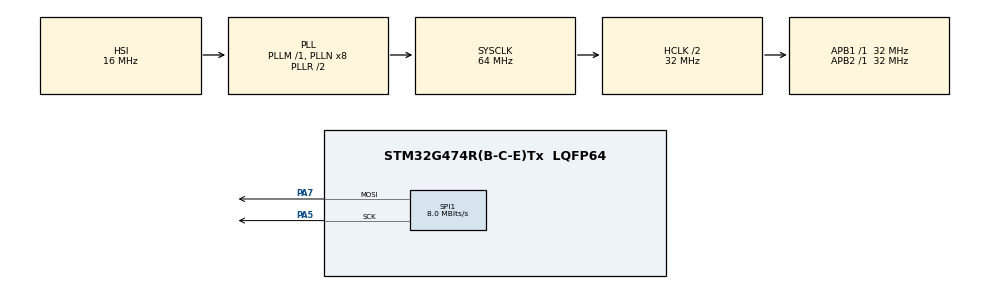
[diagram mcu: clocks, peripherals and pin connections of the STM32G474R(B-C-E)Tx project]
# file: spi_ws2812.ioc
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Mcu.Family=STM32G4
Mcu.Name=STM32G474R(B-C-E)Tx
Mcu.Package=LQFP64
NVIC.PriorityGroup=NVIC_PRIORITYGROUP_4
PA5.GPIO_Speed=GPIO_SPEED_FREQ_HIGH
PA5.Mode=TX_Only_Simplex_Unidirect_Master
PA5.Signal=SPI1_SCK
PA7.GPIO_Speed=GPIO_SPEED_FREQ_HIGH
PA7.Mode=TX_Only_Simplex_Unidirect_Master
PA7.Signal=SPI1_MOSI
PF0-OSC_IN.Mode=HSE-External-Oscillator
PF0-OSC_IN.Signal=RCC_OSC_IN
PF1-OSC_OUT.Mode=HSE-External-Oscillator
PF1-OSC_OUT.Signal=RCC_OSC_OUT
ProjectManager.HeapSize=0x200
ProjectManager.StackSize=0x400
ProjectManager.TargetToolchain=STM32CubeIDE
RCC.ADC12Freq_Value=64000000
RCC.ADC345Freq_Value=64000000
RCC.AHBCLKDivider=RCC_SYSCLK_DIV2
RCC.AHBFreq_Value=32000000
RCC.APB1Freq_Value=32000000
RCC.APB1TimFreq_Value=32000000
RCC.APB2Freq_Value=32000000
RCC.APB2TimFreq_Value=32000000
RCC.CortexFreq_Value=32000000
RCC.EXTERNAL_CLOCK_VALUE=12288000
RCC.HCLKFreq_Value=32000000
RCC.HSE_VALUE=20000000
RCC.HSI48_VALUE=48000000
RCC.HSI_VALUE=16000000
RCC.LSE_VALUE=32768
RCC.SYSCLKFreq_VALUE=64000000
RCC.SYSCLKSource=RCC_SYSCLKSOURCE_PLLCLK
RCC.USBFreq_Value=64000000
RCC.VCOOutputFreq_Value=128000000
SPI1.BaudRatePrescaler=SPI_BAUDRATEPRESCALER_4
SPI1.CLKPolarity=SPI_POLARITY_HIGH
SPI1.CalculateBaudRate=8.0 MBits/s
SPI1.DataSize=SPI_DATASIZE_8BIT
SPI1.Direction=SPI_DIRECTION_2LINES
SPI1.Mode=SPI_MODE_MASTER
SPI1.VirtualType=VM_MASTER
VP_SYS_VS_DBSignals.Mode=DisableDeadBatterySignals
board=custom

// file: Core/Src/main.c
/* USER CODE BEGIN Header */
/**
  ******************************************************************************
  * @file           : main.c
  * @brief          : Main program body
  ******************************************************************************
  * @attention
  *
  * Copyright (c) 2024 STMicroelectronics.
  * All rights reserved.
  *
  * This software is licensed under terms that can be found in the LICENSE file
  * in the root directory of this software component.
  * If no LICENSE file comes with this software, it is provided AS-IS.
  *
  ******************************************************************************
  */
/* USER CODE END Header */
#include "main.h"

SPI_HandleTypeDef hspi1;

void SystemClock_Config(void);
static void MX_GPIO_Init(void);
static void MX_SPI1_Init(void);

/* USER CODE BEGIN 0 */

uint8_t data_1=0b01111111;
uint8_t data_0=0b01000000;

void reset(){
	int n=40;
	for(int i=0;i<n;i++){
		uint8_t x=0b00000000;
		HAL_SPI_Transmit(&hspi1,&x, 1, 10);
	}
}

// 将 WS2812 数据位编码为 SPI 数据，并存储到编码后的数组中
void ws2812_encode(uint8_t* data, uint8_t* encoded_data , uint16_t length)
{
    for (int i = 0; i < length; i++) {
        for (int j = 0; j < 8; j++) {
            if (data[i] & (1 << (7 - j))) {
                encoded_data[i * 8 + j] = data_1; // 逻辑 1
            } else {
                encoded_data[i * 8 + j] = data_0; // 逻辑 0
            }
        }
    }
}

/* USER CODE END 0 */

int main(void)
{

  /* MCU Configuration--------------------------------------------------------*/

  /* Reset of all peripherals, Initializes the Flash interface and the Systick. */
  HAL_Init();

  /* Configure the system clock */
  SystemClock_Config();

  /* Initialize all configured peripherals */
  MX_GPIO_Init();
  MX_SPI1_Init();
  /* USER CODE BEGIN 2 */

  //GRB
  uint8_t led_data[3] = { 0, 255, 255 };
  uint8_t led_zero[3] = { 0, 0, 0 };
  // 分配存储编码后数据的数组
  uint8_t encoded_data[8 * sizeof(led_data)/sizeof(uint8_t)];
  uint8_t encoded_zero[8 * sizeof(led_zero)/sizeof(uint8_t)];
  // 编码数据
  ws2812_encode(led_data, encoded_data, sizeof(led_data)/sizeof(uint8_t));
  ws2812_encode(led_zero, encoded_zero, sizeof(led_zero)/sizeof(uint8_t));
  uint8_t j=0;
  reset();

  /* USER CODE END 2 */

  /* Infinite loop */
  while (1)
  {

    /* USER CODE BEGIN 3 */
	for(uint8_t i = 0;i < j - 1; i++)
	{
	  HAL_SPI_Transmit(&hspi1,encoded_zero,sizeof(encoded_zero), 10);
	}
	HAL_SPI_Transmit(&hspi1,encoded_data,sizeof(encoded_data), 10);
	reset();
	j++;
	if(j == 66)j = 1;
	HAL_Delay(50);
  }
  /* USER CODE END 3 */
}

void SystemClock_Config(void)
{
  RCC_OscInitTypeDef RCC_OscInitStruct = {0};
  RCC_ClkInitTypeDef RCC_ClkInitStruct = {0};

  /** Configure the main internal regulator output voltage
  */
  HAL_PWREx_ControlVoltageScaling(PWR_REGULATOR_VOLTAGE_SCALE1);

  /** Initializes the RCC Oscillators according to the specified parameters
  * in the RCC_OscInitTypeDef structure.
  */
  RCC_OscInitStruct.OscillatorType = RCC_OSCILLATORTYPE_HSI;
  RCC_OscInitStruct.HSIState = RCC_HSI_ON;
  RCC_OscInitStruct.HSICalibrationValue = RCC_HSICALIBRATION_DEFAULT;
  RCC_OscInitStruct.PLL.PLLState = RCC_PLL_ON;
  RCC_OscInitStruct.PLL.PLLSource = RCC_PLLSOURCE_HSI;
  RCC_OscInitStruct.PLL.PLLM = RCC_PLLM_DIV1;
  RCC_OscInitStruct.PLL.PLLN = 8;
  RCC_OscInitStruct.PLL.PLLP = RCC_PLLP_DIV2;
  RCC_OscInitStruct.PLL.PLLQ = RCC_PLLQ_DIV2;
  RCC_OscInitStruct.PLL.PLLR = RCC_PLLR_DIV2;
  if (HAL_RCC_OscConfig(&RCC_OscInitStruct) != HAL_OK)
  {
    Error_Handler();
  }

  /** Initializes the CPU, AHB and APB buses clocks
  */
  RCC_ClkInitStruct.ClockType = RCC_CLOCKTYPE_HCLK|RCC_CLOCKTYPE_SYSCLK
                              |RCC_CLOCKTYPE_PCLK1|RCC_CLOCKTYPE_PCLK2;
  RCC_ClkInitStruct.SYSCLKSource = RCC_SYSCLKSOURCE_PLLCLK;
  RCC_ClkInitStruct.AHBCLKDivider = RCC_SYSCLK_DIV2;
  RCC_ClkInitStruct.APB1CLKDivider = RCC_HCLK_DIV1;
  RCC_ClkInitStruct.APB2CLKDivider = RCC_HCLK_DIV1;

  if (HAL_RCC_ClockConfig(&RCC_ClkInitStruct, FLASH_LATENCY_1) != HAL_OK)
  {
    Error_Handler();
  }
}

static void MX_SPI1_Init(void)
{

  /* SPI1 parameter configuration*/
  hspi1.Instance = SPI1;
  hspi1.Init.Mode = SPI_MODE_MASTER;
  hspi1.Init.Direction = SPI_DIRECTION_2LINES;
  hspi1.Init.DataSize = SPI_DATASIZE_8BIT;
  hspi1.Init.CLKPolarity = SPI_POLARITY_HIGH;
  hspi1.Init.CLKPhase = SPI_PHASE_1EDGE;
  hspi1.Init.NSS = SPI_NSS_SOFT;
  hspi1.Init.BaudRatePrescaler = SPI_BAUDRATEPRESCALER_4;
  hspi1.Init.FirstBit = SPI_FIRSTBIT_MSB;
  hspi1.Init.TIMode = SPI_TIMODE_DISABLE;
  hspi1.Init.CRCCalculation = SPI_CRCCALCULATION_DISABLE;
  hspi1.Init.CRCPolynomial = 7;
  hspi1.Init.CRCLength = SPI_CRC_LENGTH_DATASIZE;
  hspi1.Init.NSSPMode = SPI_NSS_PULSE_ENABLE;
  if (HAL_SPI_Init(&hspi1) != HAL_OK)
  {
    Error_Handler();
  }

}

static void MX_GPIO_Init(void)
{

  /* GPIO Ports Clock Enable */
  __HAL_RCC_GPIOF_CLK_ENABLE();
  __HAL_RCC_GPIOA_CLK_ENABLE();

}

void Error_Handler(void)
{
  __disable_irq();
  while (1)
  {
  }
}
